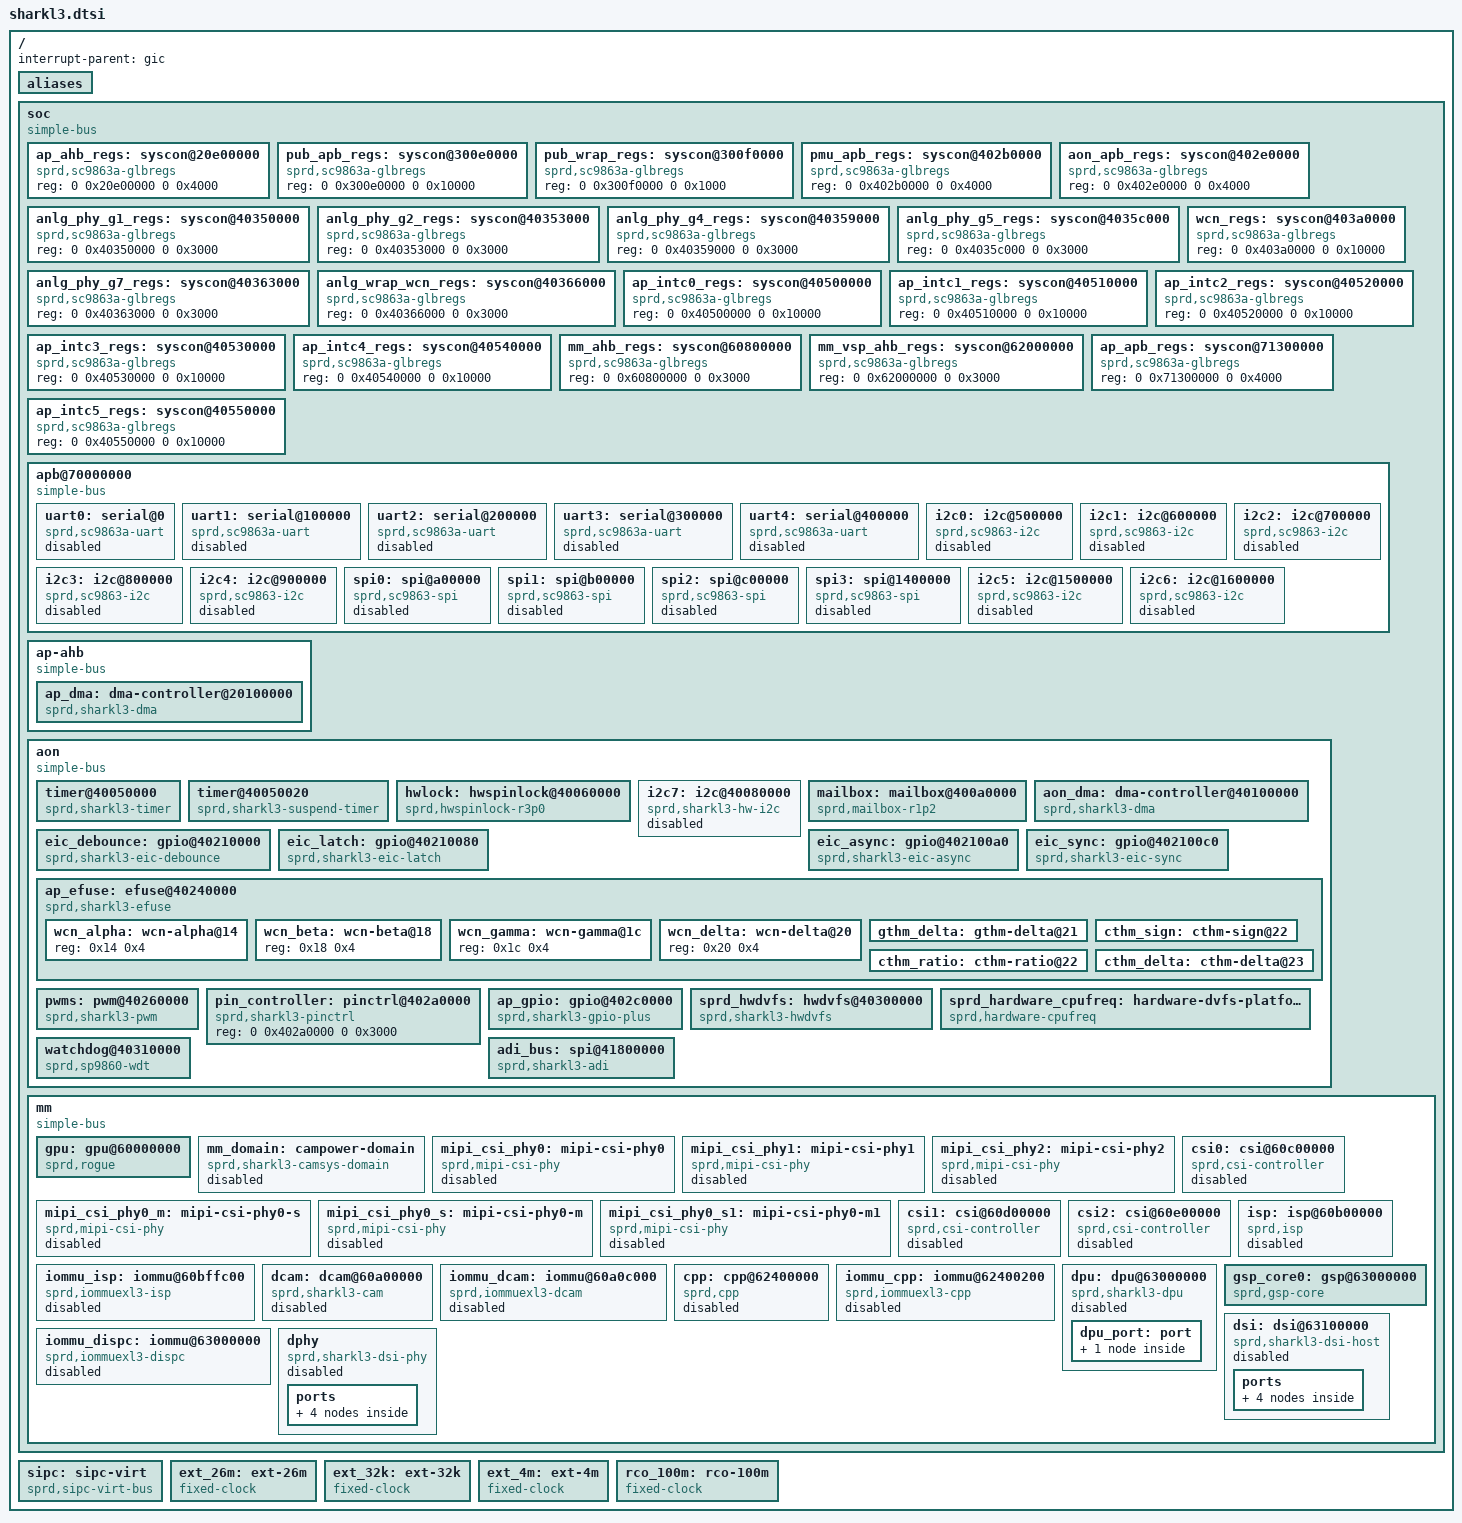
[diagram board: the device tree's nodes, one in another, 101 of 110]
// SPDX-License-Identifier: GPL-2.0-only
/*
 * Unisoc Sharkl3 platform DTS file
 *
 * Copyright (C) 2019, Unisoc Inc.
 */

#include <dt-bindings/soc/sprd,sharkl3-regs.h>
#include <dt-bindings/soc/sprd,sharkl3-mask.h>
#include <dt-bindings/clock/sprd,sc9863a-clk.h>

/ {
	interrupt-parent = <&gic>;
	#address-cells = <2>;
	#size-cells = <2>;

	aliases {
		i2c0 = &i2c0;
		i2c1 = &i2c1;
		i2c2 = &i2c2;
		i2c3 = &i2c3;
		i2c4 = &i2c4;
		i2c5 = &i2c5;
		i2c6 = &i2c6;
		i2c7 = &i2c7;
		spi0 = &spi0;
		spi1 = &spi1;
		spi2 = &spi2;
		spi3 = &spi3;
		spi4 = &adi_bus;
	};

	soc: soc {
		compatible = "simple-bus";
		#address-cells = <2>;
		#size-cells = <2>;
		ranges;

		ap_ahb_regs: syscon@20e00000 {
			compatible = "sprd,sc9863a-glbregs", "syscon";
			reg = <0 0x20e00000 0 0x4000>;
		};

		pub_apb_regs: syscon@300e0000 {
			compatible = "sprd,sc9863a-glbregs", "syscon";
			reg = <0 0x300e0000 0 0x10000>;
		};

		pub_wrap_regs: syscon@300f0000 {
			compatible = "sprd,sc9863a-glbregs", "syscon";
			reg = <0 0x300f0000 0 0x1000>;
		};

		pmu_apb_regs: syscon@402b0000 {
			compatible = "sprd,sc9863a-glbregs", "syscon";
			reg = <0 0x402b0000 0 0x4000>;
		};

		aon_apb_regs: syscon@402e0000 {
			compatible = "sprd,sc9863a-glbregs", "syscon";
			reg = <0 0x402e0000 0 0x4000>;
		};

		anlg_phy_g1_regs: syscon@40350000 {
			compatible = "sprd,sc9863a-glbregs", "syscon";
			reg = <0 0x40350000 0 0x3000>;
		};

		anlg_phy_g2_regs: syscon@40353000 {
			compatible = "sprd,sc9863a-glbregs", "syscon";
			reg = <0 0x40353000 0 0x3000>;
		};

		anlg_phy_g4_regs: syscon@40359000 {
			compatible = "sprd,sc9863a-glbregs", "syscon";
			reg = <0 0x40359000 0 0x3000>;
		};

		anlg_phy_g5_regs: syscon@4035c000 {
			compatible = "sprd,sc9863a-glbregs", "syscon";
			reg = <0 0x4035c000 0 0x3000>;
		};

		anlg_phy_g7_regs: syscon@40363000 {
			compatible = "sprd,sc9863a-glbregs", "syscon";
			reg = <0 0x40363000 0 0x3000>;
		};

		anlg_wrap_wcn_regs: syscon@40366000 {
			compatible = "sprd,sc9863a-glbregs", "syscon";
			reg = <0 0x40366000 0 0x3000>;
		};

		wcn_regs: syscon@403a0000 {
			compatible = "sprd,sc9863a-glbregs", "syscon";
			reg = <0 0x403a0000 0 0x10000>;
		};

		ap_intc0_regs: syscon@40500000 {
			compatible = "sprd,sc9863a-glbregs", "syscon";
			reg = <0 0x40500000 0 0x10000>;
		};

		ap_intc1_regs: syscon@40510000 {
			compatible = "sprd,sc9863a-glbregs", "syscon";
			reg = <0 0x40510000 0 0x10000>;
		};

		ap_intc2_regs: syscon@40520000 {
			compatible = "sprd,sc9863a-glbregs", "syscon";
			reg = <0 0x40520000 0 0x10000>;
		};

		ap_intc3_regs: syscon@40530000 {
			compatible = "sprd,sc9863a-glbregs", "syscon";
			reg = <0 0x40530000 0 0x10000>;
		};

		ap_intc4_regs: syscon@40540000 {
			compatible = "sprd,sc9863a-glbregs", "syscon";
			reg = <0 0x40540000 0 0x10000>;
		};

		mm_ahb_regs: syscon@60800000 {
			compatible = "sprd,sc9863a-glbregs", "syscon";
			reg = <0 0x60800000 0 0x3000>;
		};

		mm_vsp_ahb_regs: syscon@62000000 {
			compatible = "sprd,sc9863a-glbregs", "syscon";
			reg = <0 0x62000000 0 0x3000>;
		};

		ap_apb_regs: syscon@71300000 {
			compatible = "sprd,sc9863a-glbregs", "syscon";
			reg = <0 0x71300000 0 0x4000>;
		};

		ap_intc5_regs: syscon@40550000 {
			compatible = "sprd,sc9863a-glbregs", "syscon";
			reg = <0 0x40550000 0 0x10000>;
		};

		apb@70000000 {
			compatible = "simple-bus";
			#address-cells = <1>;
			#size-cells = <1>;
			ranges = <0 0x0 0x70000000 0x10000000>;

			uart0: serial@0 {
				compatible = "sprd,sc9863a-uart",
					     "sprd,sc9836-uart";
				reg = <0x0 0x100>;
				interrupts = <GIC_SPI 2 IRQ_TYPE_LEVEL_HIGH>;
				clocks = <&ext_26m>;
				status = "disabled";
			};

			uart1: serial@100000 {
				compatible = "sprd,sc9863a-uart",
					     "sprd,sc9836-uart";
				reg = <0x100000 0x100>;
				interrupts = <GIC_SPI 3 IRQ_TYPE_LEVEL_HIGH>;
				clocks = <&ext_26m>;
				status = "disabled";
			};

			uart2: serial@200000 {
				compatible = "sprd,sc9863a-uart",
					     "sprd,sc9836-uart";
				reg = <0x200000 0x100>;
				interrupts = <GIC_SPI 4 IRQ_TYPE_LEVEL_HIGH>;
				clocks = <&ext_26m>;
				status = "disabled";
			};

			uart3: serial@300000 {
				compatible = "sprd,sc9863a-uart",
					     "sprd,sc9836-uart";
				reg = <0x300000 0x100>;
				interrupts = <GIC_SPI 5 IRQ_TYPE_LEVEL_HIGH>;
				clocks = <&ext_26m>;
				status = "disabled";
			};

			uart4: serial@400000 {
				compatible = "sprd,sc9863a-uart",
					     "sprd,sc9836-uart";
				reg = <0x400000 0x100>;
				interrupts = <GIC_SPI 6 IRQ_TYPE_LEVEL_HIGH>;
				clocks = <&ext_26m>;
				status = "disabled";
			};

			i2c0: i2c@500000 {
				compatible = "sprd,sc9863-i2c", "sprd,sc9860-i2c";
				reg = <0x500000 0x1000>;
				interrupts = <GIC_SPI 11 IRQ_TYPE_LEVEL_HIGH>;
				clock-names = "enable", "i2c", "source";
				clock-frequency = <100000>;
				#address-cells = <1>;
				#size-cells = <0>;
				status = "disabled";
			};

			i2c1: i2c@600000 {
				compatible = "sprd,sc9863-i2c", "sprd,sc9860-i2c";
				reg = <0x600000 0x1000>;
				interrupts = <GIC_SPI 12 IRQ_TYPE_LEVEL_HIGH>;
				clock-names = "enable", "i2c", "source";
				clock-frequency = <100000>;
				#address-cells = <1>;
				#size-cells = <0>;
				status = "disabled";
			};

			i2c2: i2c@700000 {
				compatible = "sprd,sc9863-i2c", "sprd,sc9860-i2c";
				reg = <0x700000 0x1000>;
				interrupts = <GIC_SPI 13 IRQ_TYPE_LEVEL_HIGH>;
				clock-names = "enable", "i2c", "source";
				clock-frequency = <100000>;
				#address-cells = <1>;
				#size-cells = <0>;
				status = "disabled";
			};

			i2c3: i2c@800000 {
				compatible = "sprd,sc9863-i2c", "sprd,sc9860-i2c";
				reg = <0x800000 0x1000>;
				interrupts = <GIC_SPI 14 IRQ_TYPE_LEVEL_HIGH>;
				clock-names = "enable", "i2c", "source";
				clock-frequency = <400000>;
				#address-cells = <1>;
				#size-cells = <0>;
				status = "disabled";
			};

			i2c4: i2c@900000 {
				compatible = "sprd,sc9863-i2c", "sprd,sc9860-i2c";
				reg = <0x900000 0x1000>;
				interrupts = <GIC_SPI 15 IRQ_TYPE_LEVEL_HIGH>;
				clock-names = "enable","i2c", "source";
				clock-frequency = <100000>;
				#address-cells = <1>;
				#size-cells = <0>;
				status = "disabled";
			};

			spi0: spi@a00000 {
				compatible = "sprd,sc9863-spi";
				reg = <0xa00000 0x1000>;
				interrupts = <GIC_SPI 7 IRQ_TYPE_LEVEL_HIGH>;
				#address-cells = <1>;
				#size-cells = <0>;
				status = "disabled";
			};
			spi1: spi@b00000 {
				compatible = "sprd,sc9863-spi";
				reg = <0xb00000 0x1000>;
				interrupts = <GIC_SPI 8 IRQ_TYPE_LEVEL_HIGH>;
				#address-cells = <1>;
				#size-cells = <0>;
				status = "disabled";
			};
			spi2: spi@c00000 {
				compatible = "sprd,sc9863-spi";
				reg = <0xc00000 0x1000>;
				interrupts = <GIC_SPI 9 IRQ_TYPE_LEVEL_HIGH>;
				#address-cells = <1>;
				#size-cells = <0>;
				status = "disabled";
			};
			spi3: spi@1400000 {
				compatible = "sprd,sc9863-spi";
				reg = <0x1400000 0x1000>;
				interrupts = <GIC_SPI 19 IRQ_TYPE_LEVEL_HIGH>;
				#address-cells = <1>;
				#size-cells = <0>;
				status = "disabled";
			};

			i2c5: i2c@1500000 {
				compatible = "sprd,sc9863-i2c", "sprd,sc9860-i2c";
				reg = <0x1500000 0x1000>;
				interrupts = <GIC_SPI 116 IRQ_TYPE_LEVEL_HIGH>;
				clock-names = "enable","i2c", "source";
				clock-frequency = <100000>;
				#address-cells = <1>;
				#size-cells = <0>;
				status = "disabled";
			};

			i2c6: i2c@1600000 {
				compatible = "sprd,sc9863-i2c", "sprd,sc9860-i2c";
				reg = <0x1600000 0x1000>;
				interrupts = <GIC_SPI 117 IRQ_TYPE_LEVEL_HIGH>;
				clock-names = "enable","i2c", "source";
				clock-frequency = <100000>;
				#address-cells = <1>;
				#size-cells = <0>;
				status = "disabled";
			};
		};

		ap-ahb {
			compatible = "simple-bus";
			#address-cells = <2>;
			#size-cells = <2>;
			ranges;

			ap_dma: dma-controller@20100000 {
				compatible = "sprd,sharkl3-dma", "sprd,sc9860-dma";
				reg = <0 0x20100000 0 0x4000>;
				interrupts = <GIC_SPI 50 IRQ_TYPE_LEVEL_HIGH>;
				#dma-cells = <1>;
				#dma-channels = <28>;
				clock-names = "enable";
				clocks = <&apahb_gate CLK_DMA_EB>;
			};
		};

		aon {
			compatible = "simple-bus";
			#address-cells = <2>;
			#size-cells = <2>;
			ranges;

			timer@40050000 {
				compatible = "sprd,sharkl3-timer",
						"sprd,sc9860-timer";
				reg = <0 0x40050000 0 0x14>;
				interrupts = <GIC_SPI 27 IRQ_TYPE_LEVEL_HIGH>;
				clocks = <&ext_32k>;
			};

			timer@40050020 {
				compatible = "sprd,sharkl3-suspend-timer",
						"sprd,sc9860-suspend-timer";
				reg = <0 0x40050020 0 0x14>;
				clocks = <&ext_32k>;
			};

			hwlock: hwspinlock@40060000 {
				compatible = "sprd,hwspinlock-r3p0";
				reg = <0 0x40060000 0 0x10000>;
				#hwlock-cells = <1>;
				clock-names = "enable";
				clocks = <&aonapb_gate CLK_SPLK_EB>;
			};

			i2c7: i2c@40080000 {
				compatible = "sprd,sharkl3-hw-i2c";
				reg = <0 0x40080000 0 0x1000>;
				interrupts = <GIC_SPI 34 IRQ_TYPE_LEVEL_HIGH>;
				clock-names = "enable","i2c", "source",
					"clk_hw_i2c";
				clock-frequency = <100000>;
				#address-cells = <1>;
				#size-cells = <0>;
				status = "disabled";
			};

			mailbox: mailbox@400a0000 {
				compatible = "sprd,mailbox-r1p2";
				reg = <0 0x400a0000 0 0x8000>,
				      <0 0x400a8000 0 0x8000>;
				reg-names = "inbox", "outbox";
				clocks = <&aonapb_gate CLK_MBOX_EB>;
				clock-names = "enable";
				interrupts = <GIC_SPI 68 IRQ_TYPE_LEVEL_HIGH>,
					     <GIC_SPI 69 IRQ_TYPE_LEVEL_HIGH>,
					     <GIC_SPI 119 IRQ_TYPE_LEVEL_HIGH>;
				interrupt-names = "inbox", "outbox", "oob-outbox";
				#mbox-cells = <2>;
			};

			aon_dma: dma-controller@40100000 {
				compatible = "sprd,sharkl3-dma", "sprd,sc9860-dma";
				reg = <0 0x40100000 0 0x4000>;
				#dma-cells = <1>;
				#dma-channels = <9>;
				clock-names = "enable";
				clocks = <&aonapb_gate CLK_AON_DMA_EB>;
			};

			eic_debounce: gpio@40210000 {
				compatible = "sprd,sharkl3-eic-debounce";
				reg = <0 0x40210000 0 0x80>,
				      <0 0x40370000 0 0x80>;
				gpio-controller;
				#gpio-cells = <2>;
				interrupt-controller;
				#interrupt-cells = <2>;
				interrupts = <GIC_SPI 37 IRQ_TYPE_LEVEL_HIGH>;
			};

			eic_latch: gpio@40210080 {
				compatible = "sprd,sharkl3-eic-latch";
				reg = <0 0x40210080 0 0x20>,
				      <0 0x40370080 0 0x20>;
				gpio-controller;
				#gpio-cells = <2>;
				interrupt-controller;
				#interrupt-cells = <2>;
				interrupts = <GIC_SPI 37 IRQ_TYPE_LEVEL_HIGH>;
			};

			eic_async: gpio@402100a0 {
				compatible = "sprd,sharkl3-eic-async";
				reg = <0 0x402100a0 0 0x20>,
				      <0 0x403700a0 0 0x20>;
				gpio-controller;
				#gpio-cells = <2>;
				interrupt-controller;
				#interrupt-cells = <2>;
				interrupts = <GIC_SPI 37 IRQ_TYPE_LEVEL_HIGH>;
			};

			eic_sync: gpio@402100c0 {
				compatible = "sprd,sharkl3-eic-sync";
				reg = <0 0x402100c0 0 0x20>,
				      <0 0x403700c0 0 0x20>;
				gpio-controller;
				#gpio-cells = <2>;
				interrupt-controller;
				#interrupt-cells = <2>;
				interrupts = <GIC_SPI 37 IRQ_TYPE_LEVEL_HIGH>;
			};

			ap_efuse: efuse@40240000 {
				compatible = "sprd,sharkl3-efuse";
				reg = <0 0x40240000 0 0x10000>;
				#address-cells = <1>;
				#size-cells = <1>;
				clock-names = "enable";
				hwlocks = <&hwlock 8>;
				clocks = <&aonapb_gate CLK_EFUSE_EB>;

				wcn_alpha: wcn-alpha@14 {
					reg = <0x14 0x4>;
				};

				wcn_beta: wcn-beta@18 {
					reg = <0x18 0x4>;
				};

				wcn_gamma: wcn-gamma@1c {
					reg = <0x1c 0x4>;
				};

				wcn_delta: wcn-delta@20 {
					reg = <0x20 0x4>;
				};

				gthm_delta: gthm-delta@21{
					reg = <0x21 0x4>;
					bits = <1 7>;
				};

				cthm_sign: cthm-sign@22{
					reg = <0x22 0x4>;
					bits = <0 1>;
				};

				cthm_ratio: cthm-ratio@22{
					reg = <0x22 0x4>;
					bits = <1 7>;
				};

				cthm_delta: cthm-delta@23{
					reg = <0x23 0x4>;
					bits = <0 7>;
				};
			};

			pwms: pwm@40260000 {
				compatible = "sprd,sharkl3-pwm", "sprd,ums512-pwm";
				reg = <0 0x40260000 0 0x10000>;
				clock-names = "pwm0", "enable0",
					"pwm1", "enable1",
					"pwm2", "enable2";
				clocks = <&aon_clk CLK_PWM0>, <&aonapb_gate CLK_PWM0_EB>,
					<&aon_clk CLK_PWM1>, <&aonapb_gate CLK_PWM1_EB>,
					<&aon_clk CLK_PWM2>, <&aonapb_gate CLK_PWM2_EB>;
				assigned-clocks = <&aon_clk CLK_PWM0>,
					<&aon_clk CLK_PWM1>,
					<&aon_clk CLK_PWM2>;
				assigned-clock-parents = <&ext_26m>,
					<&ext_26m>,
					<&ext_26m>;
				#pwm-cells = <2>;
			};

			pin_controller: pinctrl@402a0000 {
				compatible = "sprd,sharkl3-pinctrl";
				reg = <0 0x402a0000 0 0x3000>;
			};

			ap_gpio: gpio@402c0000 {
				compatible = "sprd,sharkl3-gpio-plus";
				reg = <0 0x402c0000 0 0x1000>;
				gpio-controller;
				#gpio-cells = <2>;
				interrupt-controller;
				#interrupt-cells = <2>;
				interrupts = <GIC_SPI 130 IRQ_TYPE_LEVEL_HIGH>;
			};

			sprd_hwdvfs: hwdvfs@40300000 {
				compatible = "sprd,sharkl3-hwdvfs";
				sprd,syscon-enable = <&aon_apb_regs>;
				sprd,anlg-phy-g4-ctrl = <&anlg_phy_g4_regs>;
				reg = <0 0x40300000 0 0x1000>;
				interrupts = <GIC_SPI 121 IRQ_TYPE_LEVEL_HIGH>;
				#address-cells = <2>;
				#size-cells = <0>;
			};

			sprd_hardware_cpufreq: hardware-dvfs-platform {
				compatible = "sprd,hardware-cpufreq";
			};

			watchdog@40310000 {
				compatible = "sprd,sp9860-wdt";
				reg = <0 0x40310000 0 0x1000>;
				interrupts = <GIC_SPI 124 IRQ_TYPE_LEVEL_HIGH>;
				timeout-sec = <30>;
				clock-names = "enable", "rtc_enable";
				clocks = <&aonapb_gate CLK_CA53_WDG_EB>,
					<&aonapb_gate CLK_CA53_WDG_RTC_EB>;
			};

			adi_bus: spi@41800000 {
				compatible = "sprd,sharkl3-adi";
				reg = <0 0x41800000 0 0x200000>;
				#address-cell = <1>;
				#size-cell = <0>;
			};

		};

		mm {
			compatible = "simple-bus";
			#address-cells = <2>;
			#size-cells = <2>;
			ranges;

			gpu: gpu@60000000 {
				compatible = "sprd,rogue";
				reg = <0x0 0x60000000 0x0 0x100000>;
				top_force_shutdown = <&pmu_apb_regs
					REG_PMU_APB_PD_GPU_TOP_CFG
					MASK_PMU_APB_PD_GPU_TOP_FORCE_SHUTDOWN>;
				core_force_shutdown = <&pmu_apb_regs
					REG_PMU_APB_PD_GPU_CORE_CFG
					MASK_PMU_APB_PD_GPU_CORE_FORCE_SHUTDOWN>;
				core_auto_shutdown = <&pmu_apb_regs
					REG_PMU_APB_PD_GPU_CORE_CFG
					MASK_PMU_APB_PD_GPU_CORE_AUTO_SHUTDOWN_EN>;
				interrupts = <GIC_SPI 39 IRQ_TYPE_LEVEL_HIGH>;

				operating-points = <
					/* kHz    uV */
					256000    0
					384000    0
					550000    0
					>;

				sprd,dvfs-lists = <
					/* kHz  uV  idx div */
					256000  0    5   1
					384000  0    7   1
					550000  0    9   1
					>;

				sprd,dvfs-default = <0>;
				sprd,dvfs-scene-extreme = <2>;
				sprd,dvfs-scene-high = <1>;
				sprd,dvfs-scene-medium = <1>;
				sprd,dvfs-scene-low = <0>;
				sprd,dvfs-range-max = <2>;
				sprd,dvfs-range-min = <0>;
				};

			mm_domain: campower-domain {
				compatible = "sprd,sharkl3-camsys-domain";
				shutdown-en = <&pmu_apb_regs
					REG_PMU_APB_PD_MM_TOP_CFG
					MASK_PMU_APB_PD_MM_TOP_AUTO_SHUTDOWN_EN>;
				force-shutdown = <&pmu_apb_regs
					REG_PMU_APB_PD_MM_TOP_CFG
					MASK_PMU_APB_PD_MM_TOP_FORCE_SHUTDOWN>;
				pwr-status0 = <&pmu_apb_regs
					REG_PMU_APB_PWR_STATUS0_DBG
					0xf8000000>;
				bus-status0 = <&pmu_apb_regs
					REG_PMU_APB_BUS_STATUS0
					0x80000>;
				init-dis-bits = <&aon_apb_regs
					REG_AON_APB_AON_CLK_TOP_CFG
					(MASK_AON_APB_CLK_MM_EMC_EB |
					MASK_AON_APB_CLK_MM_AHB_EB |
					MASK_AON_APB_CLK_SENSOR2_EB |
					MASK_AON_APB_CLK_DCAM_IF_EB |
					MASK_AON_APB_CLK_ISP_EB |
					MASK_AON_APB_CLK_JPG_EB |
					MASK_AON_APB_CLK_CPP_EB |
					MASK_AON_APB_CLK_SENSOR0_EB |
					MASK_AON_APB_CLK_SENSOR1_EB |
					MASK_AON_APB_CLK_MM_VSP_EMC_EB |
					MASK_AON_APB_CLK_MM_VSP_AHB_EB |
					MASK_AON_APB_CLK_VSP_EB)>;
				#power-domain-cells = <0>;
				status = "disabled";
			};

			mipi_csi_phy0: mipi-csi-phy0 {
				compatible = "sprd,mipi-csi-phy";
				sprd,phyid = <0>;
				sprd,phyname = "2p2";
				status = "disabled";
			};

			mipi_csi_phy1: mipi-csi-phy1 {
				compatible = "sprd,mipi-csi-phy";
				sprd,phyid = <1>;
				sprd,phyname = "4lane";
				status = "disabled";
			};

			mipi_csi_phy2: mipi-csi-phy2 {
				compatible = "sprd,mipi-csi-phy";
				sprd,phyid = <2>;
				sprd,phyname = "2lane";
				status = "disabled";
			};

			mipi_csi_phy0_m: mipi-csi-phy0-s {
				compatible = "sprd,mipi-csi-phy";
				sprd,phyid = <3>;
				sprd,phyname = "2p2_m";
				status = "disabled";
			};

			mipi_csi_phy0_s: mipi-csi-phy0-m {
				compatible = "sprd,mipi-csi-phy";
				sprd,phyid = <4>;
				sprd,phyname = "2p2_s";
				status = "disabled";
			};

			mipi_csi_phy0_s1: mipi-csi-phy0-m1 {
				compatible = "sprd,mipi-csi-phy";
				sprd,phyid = <4>;
				sprd,phyname = "2p2_s";
				status = "disabled";
			};

			csi0: csi@60c00000 {
				compatible = "sprd,csi-controller";
				reg = <0 0x60c00000 0 0x1000>;
				interrupts = <GIC_SPI 40 IRQ_TYPE_LEVEL_HIGH>,
					<GIC_SPI 41 IRQ_TYPE_LEVEL_HIGH>;
				sprd,aon-apb-syscon = <&aon_apb_regs>;
				sprd,cam-ahb-syscon = <&mm_ahb_regs>;
				sprd,anlg_phy_g1_controller = <&anlg_phy_g1_regs>;
				sprd,csi-id = <0>;
				sprd,dcam-id = <0>;
				sprd,ip-version = <0x200>;
				status = "disabled";
			};

			csi1: csi@60d00000 {
				compatible = "sprd,csi-controller";
				reg = <0 0x60d00000 0 0x1000>;
				interrupts = <GIC_SPI 71 IRQ_TYPE_LEVEL_HIGH>,
					<GIC_SPI 72 IRQ_TYPE_LEVEL_HIGH>;
				sprd,aon-apb-syscon = <&aon_apb_regs>;
				sprd,cam-ahb-syscon = <&mm_ahb_regs>;
				sprd,anlg_phy_g1_controller = <&anlg_phy_g1_regs>;
				sprd,csi-id = <1>;
				sprd,dcam-id = <1>;
				sprd,ip-version = <0x200>;
				status = "disabled";
			};

			csi2: csi@60e00000 {
				compatible = "sprd,csi-controller";
				reg = <0 0x60e00000 0 0x1000>;
				interrupts = <GIC_SPI 156 IRQ_TYPE_LEVEL_HIGH>,
					<GIC_SPI 157 IRQ_TYPE_LEVEL_HIGH>;
				sprd,aon-apb-syscon = <&aon_apb_regs>;
				sprd,cam-ahb-syscon = <&mm_ahb_regs>;
				sprd,anlg_phy_g1_controller = <&anlg_phy_g1_regs>;
				sprd,csi-id = <2>;
				sprd,dcam-id = <2>;
				sprd,ip-version = <0x200>;
				status = "disabled";
			};

			isp: isp@60b00000 {
				compatible = "sprd,isp";
				reg = <0 0x60b00000 0 0x100000>;
				interrupts = <GIC_SPI 44 IRQ_TYPE_LEVEL_HIGH>,
					<GIC_SPI 125 IRQ_TYPE_LEVEL_HIGH>;
				interrupts_name = "ch0", "ch1";
				reset = <&mm_ahb_regs
						REG_MM_AHB_AHB_RST
						MASK_MM_AHB_ISP_LOG_SOFT_RST>;
				sprd,cam-ahb-syscon = <&mm_ahb_regs>;
				sprd,isp-count = <1>;
				iommus = <&iommu_isp>;
				status = "disabled";
			};

			iommu_isp: iommu@60bffc00 {
				compatible = "sprd,iommuexl3-isp";
				/* sharkl3 isp need pagetalbe size */
				reg = <0 0x60b00000 0 0xffc00>,
					<0 0x60bffc00 0 0x400>;
				iova-base = <0x50000000>;
				iova-size = <0x20000000>;
				reg_name = "mmu_interrupt_reg","mmu_reg";
				status = "disabled";
				#iommu-cells = <0>;
			};

			dcam: dcam@60a00000 {
				compatible = "sprd,sharkl3-cam";
				reg = <0 0x60a00000 0 0x1000>,
					<0 0x60a01000 0 0x1000>,
					<0 0x60a02000 0 0x1000>,
					<0 0x60a03000 0 0x1000>;
				reg_name = "dcam0_reg","dcam1_reg",
					"dcam2_reg","axi_ctrl_reg";
				interrupts = <GIC_SPI 45 IRQ_TYPE_LEVEL_HIGH>,
					<GIC_SPI 158 IRQ_TYPE_LEVEL_HIGH>,
					<GIC_SPI 159 IRQ_TYPE_LEVEL_HIGH>;
				interrupt-names = "dcam0", "dcam1",
					"dcam2";
				dcam_all_reset = <&mm_ahb_regs REG_MM_AHB_AHB_RST
					MASK_MM_AHB_DCAM_ALL_SOFT_RST>;
				dcam0_reset = <&mm_ahb_regs REG_MM_AHB_AHB_RST
					MASK_MM_AHB_DCAM0_SOFT_RST>;
				dcam1_reset = <&mm_ahb_regs REG_MM_AHB_AHB_RST
					MASK_MM_AHB_DCAM1_SOFT_RST>;
				dcam2_reset = <&mm_ahb_regs REG_MM_AHB_AHB_RST
					MASK_MM_AHB_DCAM2_SOFT_RST>;
				sprd,cam-ahb-syscon = <&mm_ahb_regs>;
				sprd,isp = <&isp>;
				sprd,dcam-count = <3>;
				sprd,project-id = <0>;
				iommus = <&iommu_dcam>;
				power-domains = <&mm_domain>;
				status = "disabled";
			};

			iommu_dcam: iommu@60a0c000 {
				compatible = "sprd,iommuexl3-dcam";
				reg = <0 0x60a00000 0 0xc000>,
					<0 0x60a0c000 0 0x60>;
				iova-base = <0x40000000>;
				iova-size = <0x20000000>;
				reg_name = "mmu_interrupt_reg", "mmu_reg";
				status = "disabled";
				#iommu-cells = <0>;
			};

			cpp: cpp@62400000 {
				compatible = "sprd,cpp";
				reg = <0 0x62400000 0 0x1000>;
				interrupts = <GIC_SPI 126 IRQ_TYPE_LEVEL_HIGH>;
				cpp_rst = <&mm_vsp_ahb_regs REG_MM_VSP_AHB_AHB_RST
					(MASK_MM_VSP_AHB_CPP_SOFT_RST |
					MASK_MM_VSP_AHB_CPP_PATH0_SOFT_RST |
					MASK_MM_VSP_AHB_CPP_PATH1_SOFT_RST |
					MASK_MM_VSP_AHB_CPP_DMA_SOFT_RST)>;
				path0_rst = <&mm_vsp_ahb_regs REG_MM_VSP_AHB_AHB_RST MASK_MM_VSP_AHB_CPP_PATH0_SOFT_RST>;
				path1_rst = <&mm_vsp_ahb_regs REG_MM_VSP_AHB_AHB_RST MASK_MM_VSP_AHB_CPP_PATH1_SOFT_RST>;
				dma_rst = <&mm_vsp_ahb_regs REG_MM_VSP_AHB_AHB_RST MASK_MM_VSP_AHB_CPP_DMA_SOFT_RST>;
				iommus = <&iommu_cpp>;
				power-domains = <&mm_domain>;
				status = "disabled";
			};

			iommu_cpp: iommu@62400200 {
				compatible = "sprd,iommuexl3-cpp";
				reg = <0 0x62400000 0 0x200>,
					<0 0x62400200 0 0x60>;
				iova-base = <0x60000000>;
				iova-size = <0x8000000>;
				reg_name = "mmu_interrupt_reg","mmu_reg";
				status = "disabled";
				#iommu-cells = <0>;
			};

			dpu: dpu@63000000 {
				compatible = "sprd,sharkl3-dpu";
				reg = <0x0 0x63000000 0x0 0x1000>;
				interrupts = <GIC_SPI 46 IRQ_TYPE_LEVEL_HIGH>;
				status = "disabled";
				iommus = <&iommu_dispc>;

				reset-syscon = <&aon_apb_regs REG_AON_APB_APB_RST1
						MASK_AON_APB_DISP_SOFT_RST>;

				dpu_port: port {
					dpu_out: endpoint {
						remote-endpoint = <&dsi_in>;
					};
				};
			};

			gsp_core0: gsp@63000000 {
				compatible = "sprd,gsp-core";
				reg = <0x0 0x63000000 0x0 0x2000>;
				core-id = <0>;
				kcfg-num = <16>;
				interrupts = <GIC_SPI 51 IRQ_TYPE_LEVEL_HIGH>;
				iommus = <&iommu_dispc>;
			};

			iommu_dispc: iommu@63000000 {
				compatible = "sprd,iommuexl3-dispc";
				reg = <0x0 0x63000000 0x0 0x800>,
				      <0x0 0x63000800 0x0 0x80>;
				iova-base = <0x30000000>;
				iova-size = <0x10000000>;
				reg_name = "mmu_interrupt_reg","mmu_reg";
				status = "disabled";
				#iommu-cells = <0>;
			};

			dsi: dsi@63100000 {
				compatible = "sprd,sharkl3-dsi-host";
				reg = <0x0 0x63100000 0x0 0x1000>;
				interrupts = <GIC_SPI 48 IRQ_TYPE_LEVEL_HIGH>,
					<GIC_SPI 49 IRQ_TYPE_LEVEL_HIGH>;
				status = "disabled";

				reset-syscon = <&aon_apb_regs REG_AON_APB_JVL_DUMMY 0x04>;

				ports {
					#address-cells = <1>;
					#size-cells = <0>;

					port@0 {
						reg = <0>;
						dsi_out: endpoint {
							remote-endpoint = <&dphy_in>;
						};
					};

					port@1 {
						reg = <1>;
						dsi_in: endpoint {
							remote-endpoint = <&dpu_out>;
						};
					};
				};
			};

			dphy: dphy {
				compatible = "sprd,sharkl3-dsi-phy";
				reg = <0x0 0x63100000 0x0 0x1000>;
				status = "disabled";

				enable-syscon = <&aon_apb_regs REG_AON_APB_APB_EB2
						(MASK_AON_APB_DPHY_REF_EB |
						MASK_AON_APB_DPHY_CFG_EB)>;
				power-small-syscon = <&aon_apb_regs REG_AON_APB_PWR_CTRL
						MASK_AON_APB_MIPI_DSI_PS_PD_S>;
				power-large-syscon = <&aon_apb_regs REG_AON_APB_PWR_CTRL
						MASK_AON_APB_MIPI_DSI_PS_PD_L>;
				power-iso-syscon = <&aon_apb_regs REG_AON_APB_PWR_CTRL
						MASK_AON_APB_MIPI_DSI_ISO_SW_EN>;

				ports {
					#address-cells = <1>;
					#size-cells = <0>;

					port@0 {
						reg = <0>;
						dphy_out: endpoint {
							remote-endpoint = <&panel_in>;
						};
					};

					port@1 {
						reg = <1>;
						dphy_in: endpoint {
							remote-endpoint = <&dsi_out>;
						};
					};
				};
			};
		};
	};

	sipc: sipc-virt {
		compatible = "sprd,sipc-virt-bus";
		#address-cells = <1>;
		#size-cells = <0>;
	};

	ext_26m: ext-26m {
		compatible = "fixed-clock";
		#clock-cells = <0>;
		clock-frequency = <26000000>;
		clock-output-names = "ext-26m";
	};

	ext_32k: ext-32k {
		compatible = "fixed-clock";
		#clock-cells = <0>;
		clock-frequency = <32768>;
		clock-output-names = "ext-32k";
	};

	ext_4m: ext-4m {
		compatible = "fixed-clock";
		#clock-cells = <0>;
		clock-frequency = <4000000>;
		clock-output-names = "ext-4m";
	};

	rco_100m: rco-100m {
		compatible = "fixed-clock";
		#clock-cells = <0>;
		clock-frequency = <100000000>;
		clock-output-names = "rco-100m";
	};
};
